# SKEAZ1284 register map
Vendor: Freescale Semiconductor, Inc.; Series: Kinetis_EA; File version: 1.6
CPU: CM0PLUS r0p0, little endian, no MPU, no FPU, VTOR, 2 interrupt priority bits
Registers are 8-bit, read-write, reset 0x0 unless marked. A register's access mark holds for its fields unless they carry their own. Offsets are from the block's base; [hi:lo] are bit positions; {n}, {i} and the like mark numbered series; 'fields as' and 'values as' point back to an identical list.

## NVIC — Nested Vectored Interrupt Controller
Base 0xE000E100
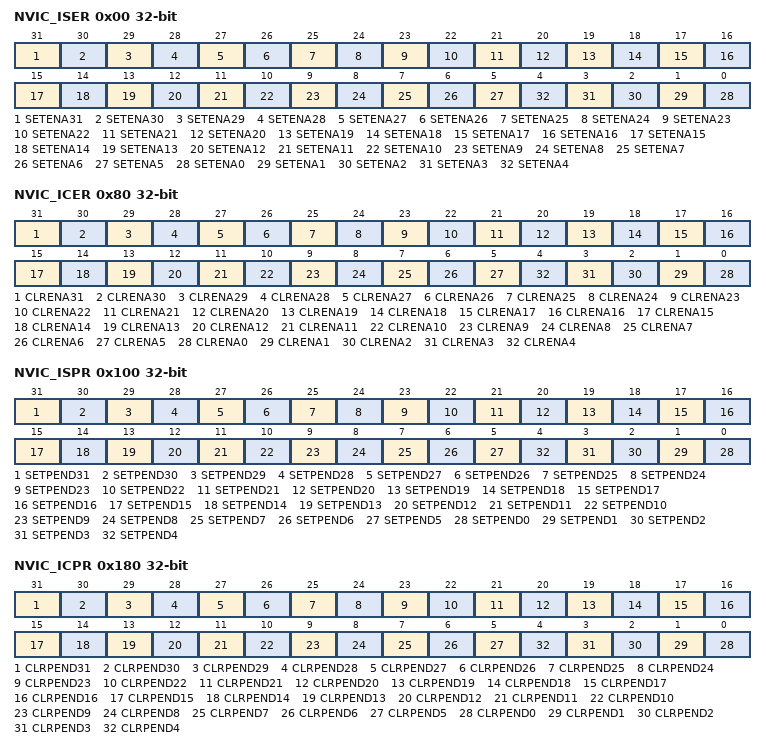
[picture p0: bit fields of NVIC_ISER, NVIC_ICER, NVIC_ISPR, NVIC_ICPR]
0x00 NVIC_ISER 32-bit — Interrupt Set Enable Register
  [31] SETENA31
    0=write: no effect; read: Freescale's Scalable Controller Area Network Tx and error interrupt disabled; 1=write: enable Freescale's Scalable Controller Area Network Tx and error interrupt; read: Freescale's Scalable Controller Area Network Tx and error interrupt enabled
  [30] SETENA30
    0=write: no effect; read: Freescale's Scalable Controller Area Network Rx interrupt disabled; 1=write: enable Freescale's Scalable Controller Area Network Rx interrupt; read: Freescale's Scalable Controller Area Network Rx interrupt enabled
  [29] SETENA29
    0=write: no effect; read: Pulse width timer interrupt disabled; 1=write: enable Pulse width timer interrupt; read: Pulse width timer interrupt enabled
  [28] SETENA28
    0=write: no effect; read: WDOG interrupt disabled; 1=write: enable WDOG interrupt; read: WDOG interrupt enabled
  [27] SETENA27
    0=write: no effect; read: Clock loss of lock interrupt disabled; 1=write: enable Clock loss of lock interrupt; read: Clock loss of lock interrupt enabled
  [26] SETENA26
    0=write: no effect; read: Reserved iv 42 interrupt disabled; 1=write: enable Reserved iv 42 interrupt; read: Reserved iv 42 interrupt enabled
  [25] SETENA25
    0=write: no effect; read: Keyboard interrupt interrupt disabled; 1=write: enable Keyboard interrupt interrupt; read: Keyboard interrupt interrupt enabled
  [24] SETENA24
    values as SETENA25
  [23] SETENA23
    0=write: no effect; read: Periodic timer overflow channel 1 interrupt disabled; 1=write: enable Periodic timer overflow channel 1 interrupt; read: Periodic timer overflow channel 1 interrupt enabled
  [22] SETENA22
    0=write: no effect; read: Periodic timer overflow channel 0 interrupt disabled; 1=write: enable Periodic timer overflow channel 0 interrupt; read: Periodic timer overflow channel 0 interrupt enabled
  [21] SETENA21
    0=write: no effect; read: Analog comparator 1 interrupt interrupt disabled; 1=write: enable Analog comparator 1 interrupt interrupt; read: Analog comparator 1 interrupt interrupt enabled
  [20] SETENA20
    0=write: no effect; read: Real-time counter interrupt disabled; 1=write: enable Real-time counter interrupt; read: Real-time counter interrupt enabled
  [19] SETENA19
    0=write: no effect; read: FlexTimer Module 2 interrupt disabled; 1=write: enable FlexTimer Module 2 interrupt; read: FlexTimer Module 2 interrupt enabled
  [18] SETENA18
    0=write: no effect; read: FlexTimer Module 1 interrupt disabled; 1=write: enable FlexTimer Module 1 interrupt; read: FlexTimer Module 1 interrupt enabled
  [17] SETENA17
    0=write: no effect; read: FlexTimer Module 0 interrupt disabled; 1=write: enable FlexTimer Module 0 interrupt; read: FlexTimer Module 0 interrupt enabled
  [16] SETENA16
    0=write: no effect; read: Analog comparator 0 interrupt interrupt disabled; 1=write: enable Analog comparator 0 interrupt interrupt; read: Analog comparator 0 interrupt interrupt enabled
  [15] SETENA15
    0=write: no effect; read: Analog-to-Digital Converter 0 interrupt disabled; 1=write: enable Analog-to-Digital Converter 0 interrupt; read: Analog-to-Digital Converter 0 interrupt enabled
  [14] SETENA14
    0=write: no effect; read: UART2 status and error interrupt disabled; 1=write: enable UART2 status and error interrupt; read: UART2 status and error interrupt enabled
  [13] SETENA13
    0=write: no effect; read: UART1 status and error interrupt disabled; 1=write: enable UART1 status and error interrupt; read: UART1 status and error interrupt enabled
  [12] SETENA12
    0=write: no effect; read: UART0 status and error interrupt disabled; 1=write: enable UART0 status and error interrupt; read: UART0 status and error interrupt enabled
  [11] SETENA11
    0=write: no effect; read: Serial Peripheral Interface 1 interrupt disabled; 1=write: enable Serial Peripheral Interface 1 interrupt; read: Serial Peripheral Interface 1 interrupt enabled
  [10] SETENA10
    0=write: no effect; read: Serial Peripheral Interface 0 interrupt disabled; 1=write: enable Serial Peripheral Interface 0 interrupt; read: Serial Peripheral Interface 0 interrupt enabled
  [9] SETENA9
    0=write: no effect; read: Inter-Integrated Circuit 1 interrupt disabled; 1=write: enable Inter-Integrated Circuit 1 interrupt; read: Inter-Integrated Circuit 1 interrupt enabled
  [8] SETENA8
    0=write: no effect; read: Inter-Integrated Circuit 0 interrupt disabled; 1=write: enable Inter-Integrated Circuit 0 interrupt; read: Inter-Integrated Circuit 0 interrupt enabled
  [7] SETENA7
    0=write: no effect; read: External Interrupt interrupt disabled; 1=write: enable External Interrupt interrupt; read: External Interrupt interrupt enabled
  [6] SETENA6
    0=write: no effect; read: Low-voltage detect, low-voltage warning interrupt disabled; 1=write: enable Low-voltage detect, low-voltage warning interrupt; read: Low-voltage detect, low-voltage warning interrupt enabled
  [5] SETENA5
    0=write: no effect; read: Command complete and read collision interrupt disabled; 1=write: enable Command complete and read collision interrupt; read: Command complete and read collision interrupt enabled
  [n] SETENA{n} (n=0..4)
    0=write: no effect; read: Reserved iv {n+16} interrupt disabled; 1=write: enable Reserved iv {n+16} interrupt; read: Reserved iv {n+16} interrupt enabled
0x80 NVIC_ICER 32-bit — Interrupt Clear Enable Register
  [31] CLRENA31
    0=write: no effect; read: Freescale's Scalable Controller Area Network Tx and error interrupt disabled; 1=write: disable Freescale's Scalable Controller Area Network Tx and error interrupt; read: Freescale's Scalable Controller Area Network Tx and error interrupt enabled
  [30] CLRENA30
    0=write: no effect; read: Freescale's Scalable Controller Area Network Rx interrupt disabled; 1=write: disable Freescale's Scalable Controller Area Network Rx interrupt; read: Freescale's Scalable Controller Area Network Rx interrupt enabled
  [29] CLRENA29
    0=write: no effect; read: Pulse width timer interrupt disabled; 1=write: disable Pulse width timer interrupt; read: Pulse width timer interrupt enabled
  [28] CLRENA28
    0=write: no effect; read: WDOG interrupt disabled; 1=write: disable WDOG interrupt; read: WDOG interrupt enabled
  [27] CLRENA27
    0=write: no effect; read: Clock loss of lock interrupt disabled; 1=write: disable Clock loss of lock interrupt; read: Clock loss of lock interrupt enabled
  [26] CLRENA26
    0=write: no effect; read: Reserved iv 42 interrupt disabled; 1=write: disable Reserved iv 42 interrupt; read: Reserved iv 42 interrupt enabled
  [25] CLRENA25
    0=write: no effect; read: Keyboard interrupt interrupt disabled; 1=write: disable Keyboard interrupt interrupt; read: Keyboard interrupt interrupt enabled
  [24] CLRENA24
    values as CLRENA25
  [23] CLRENA23
    0=write: no effect; read: Periodic timer overflow channel 1 interrupt disabled; 1=write: disable Periodic timer overflow channel 1 interrupt; read: Periodic timer overflow channel 1 interrupt enabled
  [22] CLRENA22
    0=write: no effect; read: Periodic timer overflow channel 0 interrupt disabled; 1=write: disable Periodic timer overflow channel 0 interrupt; read: Periodic timer overflow channel 0 interrupt enabled
  [21] CLRENA21
    0=write: no effect; read: Analog comparator 1 interrupt interrupt disabled; 1=write: disable Analog comparator 1 interrupt interrupt; read: Analog comparator 1 interrupt interrupt enabled
  [20] CLRENA20
    0=write: no effect; read: Real-time counter interrupt disabled; 1=write: disable Real-time counter interrupt; read: Real-time counter interrupt enabled
  [19] CLRENA19
    0=write: no effect; read: FlexTimer Module 2 interrupt disabled; 1=write: disable FlexTimer Module 2 interrupt; read: FlexTimer Module 2 interrupt enabled
  [18] CLRENA18
    0=write: no effect; read: FlexTimer Module 1 interrupt disabled; 1=write: disable FlexTimer Module 1 interrupt; read: FlexTimer Module 1 interrupt enabled
  [17] CLRENA17
    0=write: no effect; read: FlexTimer Module 0 interrupt disabled; 1=write: disable FlexTimer Module 0 interrupt; read: FlexTimer Module 0 interrupt enabled
  [16] CLRENA16
    0=write: no effect; read: Analog comparator 0 interrupt interrupt disabled; 1=write: disable Analog comparator 0 interrupt interrupt; read: Analog comparator 0 interrupt interrupt enabled
  [15] CLRENA15
    0=write: no effect; read: Analog-to-Digital Converter 0 interrupt disabled; 1=write: disable Analog-to-Digital Converter 0 interrupt; read: Analog-to-Digital Converter 0 interrupt enabled
  [14] CLRENA14
    0=write: no effect; read: UART2 status and error interrupt disabled; 1=write: disable UART2 status and error interrupt; read: UART2 status and error interrupt enabled
  [13] CLRENA13
    0=write: no effect; read: UART1 status and error interrupt disabled; 1=write: disable UART1 status and error interrupt; read: UART1 status and error interrupt enabled
  [12] CLRENA12
    0=write: no effect; read: UART0 status and error interrupt disabled; 1=write: disable UART0 status and error interrupt; read: UART0 status and error interrupt enabled
  [11] CLRENA11
    0=write: no effect; read: Serial Peripheral Interface 1 interrupt disabled; 1=write: disable Serial Peripheral Interface 1 interrupt; read: Serial Peripheral Interface 1 interrupt enabled
  [10] CLRENA10
    0=write: no effect; read: Serial Peripheral Interface 0 interrupt disabled; 1=write: disable Serial Peripheral Interface 0 interrupt; read: Serial Peripheral Interface 0 interrupt enabled
  [9] CLRENA9
    0=write: no effect; read: Inter-Integrated Circuit 1 interrupt disabled; 1=write: disable Inter-Integrated Circuit 1 interrupt; read: Inter-Integrated Circuit 1 interrupt enabled
  [8] CLRENA8
    0=write: no effect; read: Inter-Integrated Circuit 0 interrupt disabled; 1=write: disable Inter-Integrated Circuit 0 interrupt; read: Inter-Integrated Circuit 0 interrupt enabled
  [7] CLRENA7
    0=write: no effect; read: External Interrupt interrupt disabled; 1=write: disable External Interrupt interrupt; read: External Interrupt interrupt enabled
  [6] CLRENA6
    0=write: no effect; read: Low-voltage detect, low-voltage warning interrupt disabled; 1=write: disable Low-voltage detect, low-voltage warning interrupt; read: Low-voltage detect, low-voltage warning interrupt enabled
  [5] CLRENA5
    0=write: no effect; read: Command complete and read collision interrupt disabled; 1=write: disable Command complete and read collision interrupt; read: Command complete and read collision interrupt enabled
  [n] CLRENA{n} (n=0..4)
    0=write: no effect; read: Reserved iv {n+16} interrupt disabled; 1=write: disable Reserved iv {n+16} interrupt; read: Reserved iv {n+16} interrupt enabled
0x100 NVIC_ISPR 32-bit — Interrupt Set Pending Register
  [31] SETPEND31
    0=write: no effect; read: Freescale's Scalable Controller Area Network Tx and error interrupt is not pending; 1=write: changes the Freescale's Scalable Controller Area Network Tx and error interrupt state to pending; read: Freescale's Scalable Controller Area Network Tx and error interrupt is pending
  [30] SETPEND30
    0=write: no effect; read: Freescale's Scalable Controller Area Network Rx interrupt is not pending; 1=write: changes the Freescale's Scalable Controller Area Network Rx interrupt state to pending; read: Freescale's Scalable Controller Area Network Rx interrupt is pending
  [29] SETPEND29
    0=write: no effect; read: Pulse width timer interrupt is not pending; 1=write: changes the Pulse width timer interrupt state to pending; read: Pulse width timer interrupt is pending
  [28] SETPEND28
    0=write: no effect; read: WDOG interrupt is not pending; 1=write: changes the WDOG interrupt state to pending; read: WDOG interrupt is pending
  [27] SETPEND27
    0=write: no effect; read: Clock loss of lock interrupt is not pending; 1=write: changes the Clock loss of lock interrupt state to pending; read: Clock loss of lock interrupt is pending
  [26] SETPEND26
    0=write: no effect; read: Reserved iv 42 interrupt is not pending; 1=write: changes the Reserved iv 42 interrupt state to pending; read: Reserved iv 42 interrupt is pending
  [25] SETPEND25
    0=write: no effect; read: Keyboard interrupt interrupt is not pending; 1=write: changes the Keyboard interrupt interrupt state to pending; read: Keyboard interrupt interrupt is pending
  [24] SETPEND24
    values as SETPEND25
  [23] SETPEND23
    0=write: no effect; read: Periodic timer overflow channel 1 interrupt is not pending; 1=write: changes the Periodic timer overflow channel 1 interrupt state to pending; read: Periodic timer overflow channel 1 interrupt is pending
  [22] SETPEND22
    0=write: no effect; read: Periodic timer overflow channel 0 interrupt is not pending; 1=write: changes the Periodic timer overflow channel 0 interrupt state to pending; read: Periodic timer overflow channel 0 interrupt is pending
  [21] SETPEND21
    0=write: no effect; read: Analog comparator 1 interrupt interrupt is not pending; 1=write: changes the Analog comparator 1 interrupt interrupt state to pending; read: Analog comparator 1 interrupt interrupt is pending
  [20] SETPEND20
    0=write: no effect; read: Real-time counter interrupt is not pending; 1=write: changes the Real-time counter interrupt state to pending; read: Real-time counter interrupt is pending
  [19] SETPEND19
    0=write: no effect; read: FlexTimer Module 2 interrupt is not pending; 1=write: changes the FlexTimer Module 2 interrupt state to pending; read: FlexTimer Module 2 interrupt is pending
  [18] SETPEND18
    0=write: no effect; read: FlexTimer Module 1 interrupt is not pending; 1=write: changes the FlexTimer Module 1 interrupt state to pending; read: FlexTimer Module 1 interrupt is pending
  [17] SETPEND17
    0=write: no effect; read: FlexTimer Module 0 interrupt is not pending; 1=write: changes the FlexTimer Module 0 interrupt state to pending; read: FlexTimer Module 0 interrupt is pending
  [16] SETPEND16
    0=write: no effect; read: Analog comparator 0 interrupt interrupt is not pending; 1=write: changes the Analog comparator 0 interrupt interrupt state to pending; read: Analog comparator 0 interrupt interrupt is pending
  [15] SETPEND15
    0=write: no effect; read: Analog-to-Digital Converter 0 interrupt is not pending; 1=write: changes the Analog-to-Digital Converter 0 interrupt state to pending; read: Analog-to-Digital Converter 0 interrupt is pending
  [14] SETPEND14
    0=write: no effect; read: UART2 status and error interrupt is not pending; 1=write: changes the UART2 status and error interrupt state to pending; read: UART2 status and error interrupt is pending
  [13] SETPEND13
    0=write: no effect; read: UART1 status and error interrupt is not pending; 1=write: changes the UART1 status and error interrupt state to pending; read: UART1 status and error interrupt is pending
  [12] SETPEND12
    0=write: no effect; read: UART0 status and error interrupt is not pending; 1=write: changes the UART0 status and error interrupt state to pending; read: UART0 status and error interrupt is pending
  [11] SETPEND11
    0=write: no effect; read: Serial Peripheral Interface 1 interrupt is not pending; 1=write: changes the Serial Peripheral Interface 1 interrupt state to pending; read: Serial Peripheral Interface 1 interrupt is pending
  [10] SETPEND10
    0=write: no effect; read: Serial Peripheral Interface 0 interrupt is not pending; 1=write: changes the Serial Peripheral Interface 0 interrupt state to pending; read: Serial Peripheral Interface 0 interrupt is pending
  [9] SETPEND9
    0=write: no effect; read: Inter-Integrated Circuit 1 interrupt is not pending; 1=write: changes the Inter-Integrated Circuit 1 interrupt state to pending; read: Inter-Integrated Circuit 1 interrupt is pending
  [8] SETPEND8
    0=write: no effect; read: Inter-Integrated Circuit 0 interrupt is not pending; 1=write: changes the Inter-Integrated Circuit 0 interrupt state to pending; read: Inter-Integrated Circuit 0 interrupt is pending
  [7] SETPEND7
    0=write: no effect; read: External Interrupt interrupt is not pending; 1=write: changes the External Interrupt interrupt state to pending; read: External Interrupt interrupt is pending
  [6] SETPEND6
    0=write: no effect; read: Low-voltage detect, low-voltage warning interrupt is not pending; 1=write: changes the Low-voltage detect, low-voltage warning interrupt state to pending; read: Low-voltage detect, low-voltage warning interrupt is pending
  [5] SETPEND5
    0=write: no effect; read: Command complete and read collision interrupt is not pending; 1=write: changes the Command complete and read collision interrupt state to pending; read: Command complete and read collision interrupt is pending
  [n] SETPEND{n} (n=0..4)
    0=write: no effect; read: Reserved iv {n+16} interrupt is not pending; 1=write: changes the Reserved iv {n+16} interrupt state to pending; read: Reserved iv {n+16} interrupt is pending
0x180 NVIC_ICPR 32-bit — Interrupt Clear Pending Register
  [31] CLRPEND31
    0=write: no effect; read: Freescale's Scalable Controller Area Network Tx and error interrupt is not pending; 1=write: removes pending state from the Freescale's Scalable Controller Area Network Tx and error interrupt; read: Freescale's Scalable Controller Area Network Tx and error interrupt is pending
  [30] CLRPEND30
    0=write: no effect; read: Freescale's Scalable Controller Area Network Rx interrupt is not pending; 1=write: removes pending state from the Freescale's Scalable Controller Area Network Rx interrupt; read: Freescale's Scalable Controller Area Network Rx interrupt is pending
  [29] CLRPEND29
    0=write: no effect; read: Pulse width timer interrupt is not pending; 1=write: removes pending state from the Pulse width timer interrupt; read: Pulse width timer interrupt is pending
  [28] CLRPEND28
    0=write: no effect; read: WDOG interrupt is not pending; 1=write: removes pending state from the WDOG interrupt; read: WDOG interrupt is pending
  [27] CLRPEND27
    0=write: no effect; read: Clock loss of lock interrupt is not pending; 1=write: removes pending state from the Clock loss of lock interrupt; read: Clock loss of lock interrupt is pending
  [26] CLRPEND26
    0=write: no effect; read: Reserved iv 42 interrupt is not pending; 1=write: removes pending state from the Reserved iv 42 interrupt; read: Reserved iv 42 interrupt is pending
  [25] CLRPEND25
    0=write: no effect; read: Keyboard interrupt interrupt is not pending; 1=write: removes pending state from the Keyboard interrupt interrupt; read: Keyboard interrupt interrupt is pending
  [24] CLRPEND24
    values as CLRPEND25
  [23] CLRPEND23
    0=write: no effect; read: Periodic timer overflow channel 1 interrupt is not pending; 1=write: removes pending state from the Periodic timer overflow channel 1 interrupt; read: Periodic timer overflow channel 1 interrupt is pending
  [22] CLRPEND22
    0=write: no effect; read: Periodic timer overflow channel 0 interrupt is not pending; 1=write: removes pending state from the Periodic timer overflow channel 0 interrupt; read: Periodic timer overflow channel 0 interrupt is pending
  [21] CLRPEND21
    0=write: no effect; read: Analog comparator 1 interrupt interrupt is not pending; 1=write: removes pending state from the Analog comparator 1 interrupt interrupt; read: Analog comparator 1 interrupt interrupt is pending
  [20] CLRPEND20
    0=write: no effect; read: Real-time counter interrupt is not pending; 1=write: removes pending state from the Real-time counter interrupt; read: Real-time counter interrupt is pending
  [19] CLRPEND19
    0=write: no effect; read: FlexTimer Module 2 interrupt is not pending; 1=write: removes pending state from the FlexTimer Module 2 interrupt; read: FlexTimer Module 2 interrupt is pending
  [18] CLRPEND18
    0=write: no effect; read: FlexTimer Module 1 interrupt is not pending; 1=write: removes pending state from the FlexTimer Module 1 interrupt; read: FlexTimer Module 1 interrupt is pending
  [17] CLRPEND17
    0=write: no effect; read: FlexTimer Module 0 interrupt is not pending; 1=write: removes pending state from the FlexTimer Module 0 interrupt; read: FlexTimer Module 0 interrupt is pending
  [16] CLRPEND16
    0=write: no effect; read: Analog comparator 0 interrupt interrupt is not pending; 1=write: removes pending state from the Analog comparator 0 interrupt interrupt; read: Analog comparator 0 interrupt interrupt is pending
  [15] CLRPEND15
    0=write: no effect; read: Analog-to-Digital Converter 0 interrupt is not pending; 1=write: removes pending state from the Analog-to-Digital Converter 0 interrupt; read: Analog-to-Digital Converter 0 interrupt is pending
  [14] CLRPEND14
    0=write: no effect; read: UART2 status and error interrupt is not pending; 1=write: removes pending state from the UART2 status and error interrupt; read: UART2 status and error interrupt is pending
  [13] CLRPEND13
    0=write: no effect; read: UART1 status and error interrupt is not pending; 1=write: removes pending state from the UART1 status and error interrupt; read: UART1 status and error interrupt is pending
  [12] CLRPEND12
    0=write: no effect; read: UART0 status and error interrupt is not pending; 1=write: removes pending state from the UART0 status and error interrupt; read: UART0 status and error interrupt is pending
  [11] CLRPEND11
    0=write: no effect; read: Serial Peripheral Interface 1 interrupt is not pending; 1=write: removes pending state from the Serial Peripheral Interface 1 interrupt; read: Serial Peripheral Interface 1 interrupt is pending
  [10] CLRPEND10
    0=write: no effect; read: Serial Peripheral Interface 0 interrupt is not pending; 1=write: removes pending state from the Serial Peripheral Interface 0 interrupt; read: Serial Peripheral Interface 0 interrupt is pending
  [9] CLRPEND9
    0=write: no effect; read: Inter-Integrated Circuit 1 interrupt is not pending; 1=write: removes pending state from the Inter-Integrated Circuit 1 interrupt; read: Inter-Integrated Circuit 1 interrupt is pending
  [8] CLRPEND8
    0=write: no effect; read: Inter-Integrated Circuit 0 interrupt is not pending; 1=write: removes pending state from the Inter-Integrated Circuit 0 interrupt; read: Inter-Integrated Circuit 0 interrupt is pending
  [7] CLRPEND7
    0=write: no effect; read: External Interrupt interrupt is not pending; 1=write: removes pending state from the External Interrupt interrupt; read: External Interrupt interrupt is pending
  [6] CLRPEND6
    0=write: no effect; read: Low-voltage detect, low-voltage warning interrupt is not pending; 1=write: removes pending state from the Low-voltage detect, low-voltage warning interrupt; read: Low-voltage detect, low-voltage warning interrupt is pending
  [5] CLRPEND5
    0=write: no effect; read: Command complete and read collision interrupt is not pending; 1=write: removes pending state from the Command complete and read collision interrupt; read: Command complete and read collision interrupt is pending
  [n] CLRPEND{n} (n=0..4)
    0=write: no effect; read: Reserved iv {n+16} interrupt is not pending; 1=write: removes pending state from the Reserved iv {n+16} interrupt; read: Reserved iv {n+16} interrupt is pending
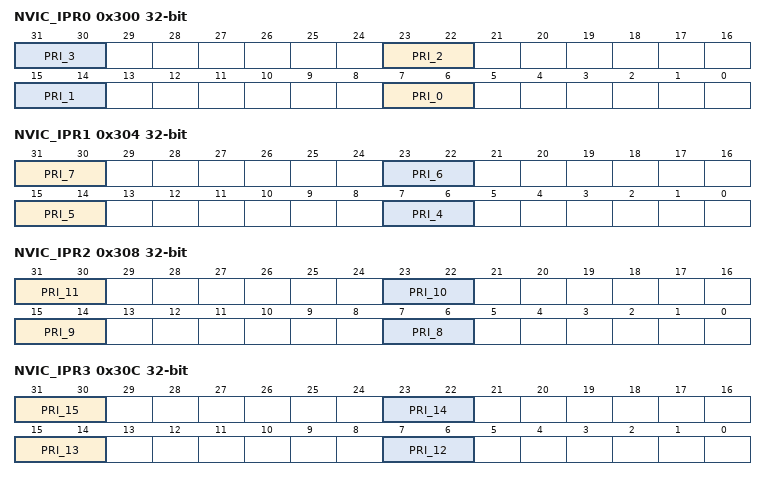
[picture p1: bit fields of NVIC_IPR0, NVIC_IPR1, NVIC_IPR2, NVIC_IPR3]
0x300 NVIC_IPR0 32-bit — Interrupt Priority Register 0
  [8n+7:8n+6] PRI_{n} (n=0..3) — Priority of the Reserved iv {n+16} interrupt
0x304 NVIC_IPR1 32-bit — Interrupt Priority Register 1
  [31:30] PRI_7 — Priority of the External Interrupt interrupt
  [23:22] PRI_6 — Priority of the Low-voltage detect, low-voltage warning interrupt
  [15:14] PRI_5 — Priority of the Command complete and read collision interrupt
  [7:6] PRI_4 — Priority of the Reserved iv 20 interrupt
0x308 NVIC_IPR2 32-bit — Interrupt Priority Register 2
  [31:30] PRI_11 — Priority of the Serial Peripheral Interface 1 interrupt
  [23:22] PRI_10 — Priority of the Serial Peripheral Interface 0 interrupt
  [15:14] PRI_9 — Priority of the Inter-Integrated Circuit 1 interrupt
  [7:6] PRI_8 — Priority of the Inter-Integrated Circuit 0 interrupt
0x30C NVIC_IPR3 32-bit — Interrupt Priority Register 3
  [31:30] PRI_15 — Priority of the Analog-to-Digital Converter 0 interrupt
  [23:22] PRI_14 — Priority of the UART2 status and error interrupt
  [15:14] PRI_13 — Priority of the UART1 status and error interrupt
  [7:6] PRI_12 — Priority of the UART0 status and error interrupt
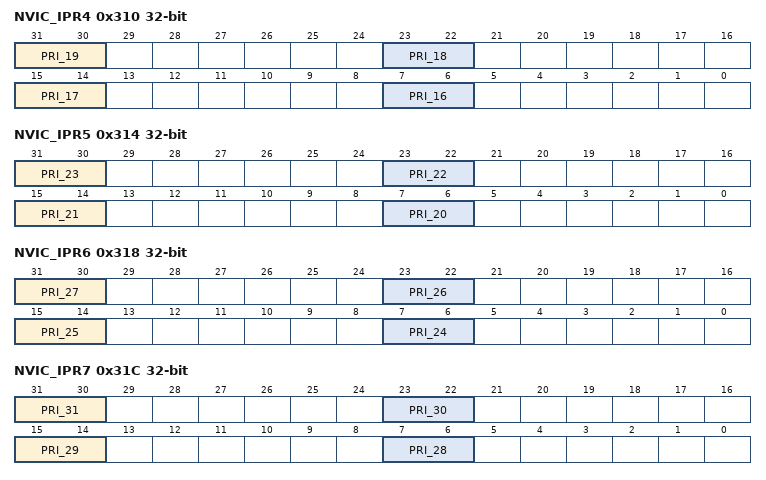
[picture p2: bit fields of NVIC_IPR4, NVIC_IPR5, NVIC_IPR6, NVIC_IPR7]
0x310 NVIC_IPR4 32-bit — Interrupt Priority Register 4
  [31:30] PRI_19 — Priority of the FlexTimer Module 2 interrupt
  [23:22] PRI_18 — Priority of the FlexTimer Module 1 interrupt
  [15:14] PRI_17 — Priority of the FlexTimer Module 0 interrupt
  [7:6] PRI_16 — Priority of the Analog comparator 0 interrupt interrupt
0x314 NVIC_IPR5 32-bit — Interrupt Priority Register 5
  [31:30] PRI_23 — Priority of the Periodic timer overflow channel 1 interrupt
  [23:22] PRI_22 — Priority of the Periodic timer overflow channel 0 interrupt
  [15:14] PRI_21 — Priority of the Analog comparator 1 interrupt interrupt
  [7:6] PRI_20 — Priority of the Real-time counter interrupt
0x318 NVIC_IPR6 32-bit — Interrupt Priority Register 6
  [31:30] PRI_27 — Priority of the Clock loss of lock interrupt
  [23:22] PRI_26 — Priority of the Reserved iv 42 interrupt
  [15:14] PRI_25 — Priority of the Keyboard interrupt interrupt
  [7:6] PRI_24 — Priority of the Keyboard interrupt interrupt
0x31C NVIC_IPR7 32-bit — Interrupt Priority Register 7
  [31:30] PRI_31 — Priority of the Freescale's Scalable Controller Area Network Tx and error interrupt
  [23:22] PRI_30 — Priority of the Freescale's Scalable Controller Area Network Rx interrupt
  [15:14] PRI_29 — Priority of the Pulse width timer interrupt
  [7:6] PRI_28 — Priority of the WDOG interrupt
